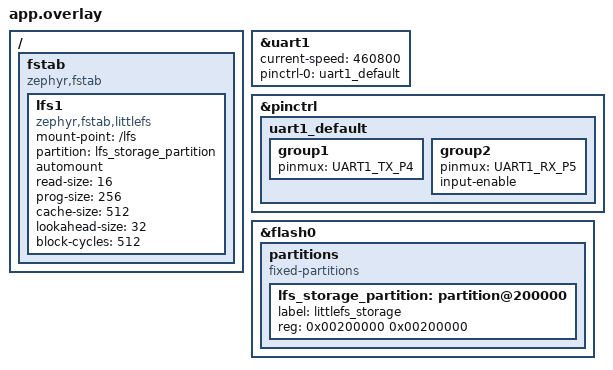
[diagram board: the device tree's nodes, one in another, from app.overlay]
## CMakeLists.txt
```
cmake_minimum_required(VERSION 3.20.0)

find_package(Zephyr REQUIRED HINTS $ENV{ZEPHYR_BASE})
project(my_project)

target_include_directories(app PRIVATE
     src
     src/app/init
    src/core/vfs/storage
    src/test/core/unity
    src/test/core/param_manager
    src/camera/core/vsc
    src/camera/core/vsc_lite
    src/camera/board
    src/camera/modules/vsc_lite
    gen/vsc
    src/test/protocols/camyu
    src/core/protocol_parser
    src/platform
    src/platform/port
    src/core/param_manager/core
    src/core/param_manager/config
    src/core/param_manager/storage
    src/protocols/ymodem/src
    src/protocols/ymodem/adapter
    src/protocols/imperx
    src/protocols/camyu
    src/core/file_process
    src/core/vfs
    src/core/vfs/backend
    src/core/vfs/rawflash
    src/lib/flashdb/inc
    src/lib/mkv
    src/lib/flashdb/port/fal/inc
    src/lib/flashdb/config
    src/lib/lwevt/src/include
    src/lib/lwevt/user_config
    src/platform/bsp/rp2350
    src/camera/modules/auto_exp
    src/camera/core/isc/core
    src/camera/core/isc/port
    src/camera/drivers/sensors
    src/camera/drivers/bridge
    src/camera/drivers/ip/binning
    src/camera/drivers/ip/crop
    src/camera/drivers/ip/decoder
    src/camera/drivers/ip/histogram
)

target_compile_definitions(app PRIVATE PARAM_MKV_ENABLE=1)

target_sources(app PRIVATE
      src/app/main.c
      src/app/init/init_thread.c
      src/app/init/protocol_chain_init.c
      src/app/init/param_manager_init.c
      src/app/init/file_storage_init.c
      src/app/init/protocol_parser_thread.c
      src/core/protocol_parser/protocol_chain.c
      src/core/protocol_parser/protocol_parser.c
      src/core/param_manager/core/param_manager.c
      src/core/param_manager/core/app_param_manager.c
      src/core/param_manager/core/ip_param_manager.c
      src/core/param_manager/core/param_data_ops.c
      src/core/param_manager/core/param_dump.c
      src/core/param_manager/core/param_service.c
      src/core/param_manager/core/param_boot.c
      src/platform/port/port_impl.c
      src/core/param_manager/storage/param_storage_flashdb.c
      src/core/param_manager/storage/param_storage_mkv.c
      src/lib/mkv/mkv.c
      src/platform/bsp/rp2350/fal_flash_rp2350.c
      src/protocols/camyu/protocol_parser_camyu.c
      src/protocols/imperx/protocol_parser_imperx.c
      src/protocols/imperx/imperx_cmd_map.c
      src/protocols/ymodem/adapter/protocol_parser_ymodem.c
      src/protocols/ymodem/src/ymodem_common.c
      src/protocols/ymodem/src/ymodem_receiver.c
      src/protocols/ymodem/src/ymodem_sender.c
      src/core/vfs/vfs_core.c
      src/core/vfs/vfs_bdev.c
      src/core/vfs/backend/vfs_rawflash.c
      src/core/vfs/backend/vfs_littlefs.c
      src/core/vfs/backend/vfs_fatfs.c
      src/core/vfs/stdio/vfs_stdio_newlib.c
      src/core/vfs/stdio/vfs_stdio_armcc.c
      src/core/vfs/storage/storage_config.c
      src/core/vfs/storage/storage_drv_fal.c
      src/core/vfs/storage/storage_drv_sd.c
      src/core/vfs/rawflash/rawflash.c
      src/lib/flashdb/src/fdb.c
      src/lib/flashdb/src/fdb_kvdb.c
      src/lib/flashdb/src/fdb_utils.c
      src/lib/flashdb/port/fal/src/fal.c
      src/lib/flashdb/port/fal/src/fal_flash.c
      src/lib/flashdb/port/fal/src/fal_partition.c
      src/lib/lwevt/src/lwevt/lwevt.c
      src/camera/modules/auto_exp/ae_instance.c
      src/camera/modules/auto_exp/auto_exp_control.c
      src/camera/drivers/bridge/sensor_module.c
      src/camera/core/isc/example_app.c
      src/camera/core/isc/core/isc_core.c
      src/camera/core/isc/port/isc_port_common.c
      src/camera/core/isc/port/isc_port_i2c.c
      src/camera/drivers/sensors/isc_sensor_imx296.c
      src/camera/core/vsc_lite/vsc_lite.c
      src/camera/board/vsc_lite_board_default.c
      src/camera/modules/vsc_lite/vsc_lite_control.c
      src/camera/drivers/bridge/sensor_vsc.c
      src/camera/drivers/bridge/sensor_imx296_vsc.c
      src/camera/drivers/bridge/isc_bridge.c
      src/camera/drivers/ip/crop/crop_vsc.c
      src/camera/drivers/ip/crop/crop_driver.c
      src/camera/drivers/ip/binning/binning_vsc.c
      src/camera/drivers/ip/binning/binning_driver.c
      src/camera/drivers/ip/decoder/decoder_vsc.c
      src/camera/drivers/ip/decoder/decoder_driver.c
      src/camera/drivers/ip/histogram/histogram_vsc.c
      src/camera/drivers/ip/histogram/histogram_driver.c
      src/camera/drivers/sensors/isc_sensor_imx477.c
  )
```

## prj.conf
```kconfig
# 系统
CONFIG_LOG=y
CONFIG_SHELL=y
CONFIG_KERNEL_SHELL=y
CONFIG_HEAP_MEM_POOL_SIZE=16384
CONFIG_MAIN_STACK_SIZE=10240
CONFIG_UART_USE_RUNTIME_CONFIGURE=y
# CONFIG_NO_OPTIMIZATIONS=y
CONFIG_SIZE_OPTIMIZATIONS=y
CONFIG_LOG_CMDS=y
CONFIG_LOG_MODE_DEFERRED=y
CONFIG_LOG_BUFFER_SIZE=4096
# UART
CONFIG_SERIAL=y
CONFIG_UART_INTERRUPT_DRIVEN=y

# Flash
CONFIG_FLASH=y
CONFIG_FLASH_MAP=y
CONFIG_FLASH_PAGE_LAYOUT=y

# libc (picolibc)
CONFIG_PICOLIBC_IO_FLOAT=y
CONFIG_NEWLIB_LIBC=y        
# CONFIG_MINIMAL_LIBC is not set

# 文件系统
CONFIG_FILE_SYSTEM=y
CONFIG_FILE_SYSTEM_LITTLEFS=y
CONFIG_FILE_SYSTEM_SHELL=y
CONFIG_FS_LITTLEFS_FC_HEAP_SIZE=4096

# MCUmgr
CONFIG_MCUMGR=y
CONFIG_MCUMGR_TRANSPORT_SHELL=y
CONFIG_MCUMGR_GRP_FS=y
CONFIG_MCUMGR_GRP_OS=y
CONFIG_MCUMGR_GRP_OS_ECHO=y
CONFIG_ZCBOR=y
CONFIG_BASE64=y
CONFIG_NET_BUF=y
CONFIG_CRC=y

CONFIG_SYSTEM_WORKQUEUE_STACK_SIZE=2560
```

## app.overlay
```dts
&uart1 {
    status = "okay";
    current-speed = <460800>;
    pinctrl-0 = <&uart1_default>;
    pinctrl-names = "default";
};

&pinctrl {
    uart1_default: uart1_default {
        group1 {
            pinmux = <UART1_TX_P4>;
        };
        group2 {
            pinmux = <UART1_RX_P5>;
            input-enable;
        };
    };
};

/ {
    fstab {
        compatible = "zephyr,fstab";

        lfs1: lfs1 {
            compatible = "zephyr,fstab,littlefs";
            mount-point = "/lfs";
            partition = <&lfs_storage_partition>;
            automount;
            read-size = <16>;
            prog-size = <256>;
            cache-size = <512>;
            lookahead-size = <32>;
            block-cycles = <512>;
        };
    };
};

&flash0 {
    partitions {
        compatible = "fixed-partitions";
        #address-cells = <1>;
        #size-cells = <1>;

        lfs_storage_partition: partition@200000 {
            label = "littlefs_storage";
            reg = <0x00200000 0x00200000>;
        };
    };
};
```

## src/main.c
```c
#include <zephyr/kernel.h>
#include <zephyr/sys/printk.h>
#include <zephyr/device.h>
#include <zephyr/drivers/uart.h>
#include "init/app_config.h"
#include "init/init_thread.h"
#include "ymodem_common.h"

#define UART1_NODE DT_NODELABEL(uart1)
const struct device *const uart1_dev = DEVICE_DT_GET(UART1_NODE);

K_THREAD_STACK_DEFINE(init_stack, INIT_STACK_SIZE);
static struct k_thread init_thread_data;

K_PIPE_DEFINE(uart_pipe, PIPE_BUFFER_SIZE, 1);

uint32_t system_get_time_ms(void)
{
    return k_uptime_get_32();
}

static void uart1_irq_callback(const struct device *dev, void *user_data)
{
    uart_irq_update(dev);
    if (uart_irq_rx_ready(dev))
    {
        uint8_t rx_buf[YMODEM_STX_FRAME_LEN_BYTE];
        int bytes_read = uart_fifo_read(dev, rx_buf, sizeof(rx_buf));
        if (bytes_read > 0)
        {
            k_pipe_write(&uart_pipe, rx_buf, (size_t)bytes_read, K_NO_WAIT);
        }
    }

    if (uart_irq_tx_ready(dev))
    {
    }
}

static void set_baud_rate(const struct device *uart_dev, uint32_t new_baud)
{
    struct uart_config cfg;
    int ret;

    ret = uart_config_get(uart_dev, &cfg);
    if (ret != 0)
    {
        printk("Error: uart_config_get() failed (%d)\n", ret);
        return;
    }
    cfg.baudrate = new_baud;

    ret = uart_configure(uart_dev, &cfg);
    if (ret == 0)
    {
        printk("UART baudrate set to %u\n", new_baud);
    }
    else
    {
        printk("Error: uart_configure() failed (%d)\n", ret);
    }
}

int main(void)
{
    printk("20260521\n");
    printk("=== Protocol Chain Test (Zephyr) ===\n");
    printk("  Protocols: Imperx, Camyu, Ymodem(Rx), Ymodem(Tx)\n");
    printk("\n");

    if (!device_is_ready(uart1_dev))
    {
        printk("Error: UART1 device not ready\n");
        return -1;
    }

    set_baud_rate(uart1_dev, TEST_BAUD_RATE);

    uart_irq_callback_user_data_set(uart1_dev, uart1_irq_callback, NULL);
    uart_irq_rx_enable(uart1_dev);

    k_thread_create(&init_thread_data, init_stack,
                    K_THREAD_STACK_SIZEOF(init_stack),
                    init_thread_entry, NULL, NULL, NULL,
                    THREAD_PRIORITY, 0, K_NO_WAIT);
    k_thread_name_set(&init_thread_data, "init");

    while (1)
    {
        k_msleep(5000);
    }
    return 0;
}
```
